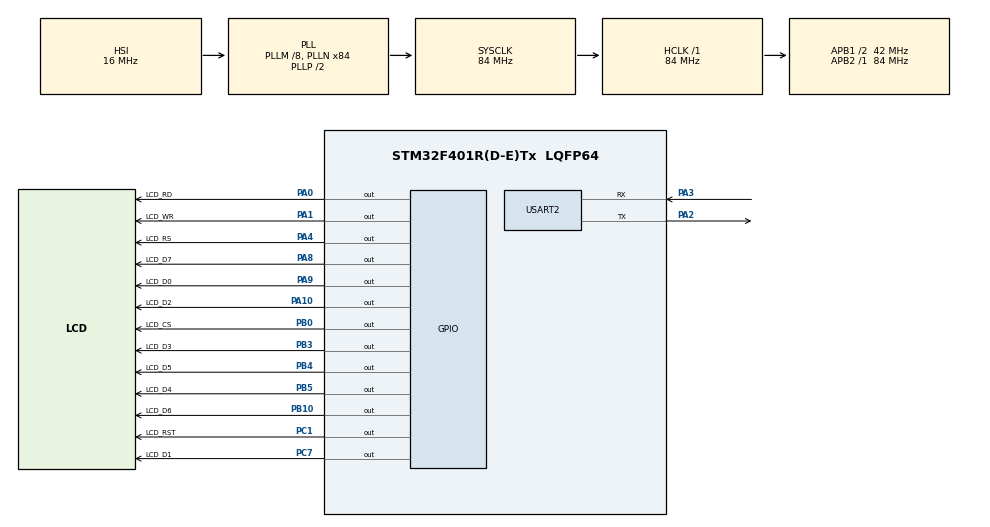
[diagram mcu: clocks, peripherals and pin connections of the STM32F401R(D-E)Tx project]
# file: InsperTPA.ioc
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Mcu.Family=STM32F4
Mcu.Name=STM32F401R(D-E)Tx
Mcu.Package=LQFP64
NVIC.PriorityGroup=NVIC_PRIORITYGROUP_4
NVIC.USART2_IRQn=true\:0\:0\:false\:false\:true\:true\:true\:true
PA0-WKUP.GPIO_Label=LCD_RD
PA0-WKUP.GPIO_PuPd=GPIO_PULLDOWN
PA0-WKUP.GPIO_Speed=GPIO_SPEED_FREQ_VERY_HIGH
PA0-WKUP.PinState=GPIO_PIN_SET
PA0-WKUP.Signal=GPIO_Output
PA1.GPIO_Label=LCD_WR
PA1.GPIO_PuPd=GPIO_PULLDOWN
PA1.GPIO_Speed=GPIO_SPEED_FREQ_VERY_HIGH
PA1.PinState=GPIO_PIN_SET
PA1.Signal=GPIO_Output
PA10.GPIO_Label=LCD_D2
PA10.GPIO_PuPd=GPIO_PULLDOWN
PA10.GPIO_Speed=GPIO_SPEED_FREQ_VERY_HIGH
PA10.Signal=GPIO_Output
PA2.Mode=Asynchronous
PA2.Signal=USART2_TX
PA3.Mode=Asynchronous
PA3.Signal=USART2_RX
PA4.GPIO_Label=LCD_RS
PA4.GPIO_PuPd=GPIO_PULLDOWN
PA4.GPIO_Speed=GPIO_SPEED_FREQ_VERY_HIGH
PA4.PinState=GPIO_PIN_SET
PA4.Signal=GPIO_Output
PA8.GPIO_Label=LCD_D7
PA8.GPIO_PuPd=GPIO_PULLDOWN
PA8.GPIO_Speed=GPIO_SPEED_FREQ_VERY_HIGH
PA8.Signal=GPIO_Output
PA9.GPIO_Label=LCD_D0
PA9.GPIO_PuPd=GPIO_PULLDOWN
PA9.GPIO_Speed=GPIO_SPEED_FREQ_VERY_HIGH
PA9.Signal=GPIO_Output
PB0.GPIO_Label=LCD_CS
PB0.GPIO_PuPd=GPIO_PULLDOWN
PB0.GPIO_Speed=GPIO_SPEED_FREQ_VERY_HIGH
PB0.PinState=GPIO_PIN_SET
PB0.Signal=GPIO_Output
PB10.GPIO_Label=LCD_D6
PB10.GPIO_PuPd=GPIO_PULLDOWN
PB10.GPIO_Speed=GPIO_SPEED_FREQ_VERY_HIGH
PB10.Signal=GPIO_Output
PB3.GPIO_Label=LCD_D3
PB3.GPIO_PuPd=GPIO_PULLDOWN
PB3.GPIO_Speed=GPIO_SPEED_FREQ_VERY_HIGH
PB3.Signal=GPIO_Output
PB4.GPIO_Label=LCD_D5
PB4.GPIO_PuPd=GPIO_PULLDOWN
PB4.GPIO_Speed=GPIO_SPEED_FREQ_VERY_HIGH
PB4.Signal=GPIO_Output
PB5.GPIO_Label=LCD_D4
PB5.GPIO_PuPd=GPIO_PULLDOWN
PB5.GPIO_Speed=GPIO_SPEED_FREQ_VERY_HIGH
PB5.Signal=GPIO_Output
PC1.GPIO_Label=LCD_RST
PC1.GPIO_ModeDefaultOutputPP=GPIO_MODE_OUTPUT_PP
PC1.GPIO_PuPd=GPIO_PULLUP
PC1.GPIO_Speed=GPIO_SPEED_FREQ_VERY_HIGH
PC1.PinState=GPIO_PIN_SET
PC1.Signal=GPIO_Output
PC7.GPIO_Label=LCD_D1
PC7.GPIO_PuPd=GPIO_PULLDOWN
PC7.GPIO_Speed=GPIO_SPEED_FREQ_VERY_HIGH
PC7.Signal=GPIO_Output
ProjectManager.HeapSize=0x200
ProjectManager.StackSize=0x400
ProjectManager.TargetToolchain=STM32CubeIDE
RCC.48MHZClocksFreq_Value=42000000
RCC.AHBFreq_Value=84000000
RCC.APB1CLKDivider=RCC_HCLK_DIV2
RCC.APB1Freq_Value=42000000
RCC.APB1TimFreq_Value=84000000
RCC.APB2Freq_Value=84000000
RCC.APB2TimFreq_Value=84000000
RCC.CortexFreq_Value=84000000
RCC.FLatency=FLASH_LATENCY_2
RCC.HCLKFreq_Value=84000000
RCC.HSE_VALUE=25000000
RCC.HSI_VALUE=16000000
RCC.LSE_VALUE=32768
RCC.PLLM=8
RCC.PLLN=84
RCC.SYSCLKFreq_VALUE=84000000
RCC.SYSCLKSource=RCC_SYSCLKSOURCE_PLLCLK
RCC.VCOOutputFreq_Value=168000000
STMicroelectronics.X-CUBE-TOUCHGFX.4.26.1.ApplicationCcGraphicsJjApplication=TouchGFXOoGenerator
STMicroelectronics.X-CUBE-TOUCHGFX.4.26.1.tgfx_block_size=19200
STMicroelectronics.X-CUBE-TOUCHGFX.4.26.1.tgfx_buffering_strategy=Partial
STMicroelectronics.X-CUBE-TOUCHGFX.4.26.1.tgfx_custom_height=320
STMicroelectronics.X-CUBE-TOUCHGFX.4.26.1.tgfx_custom_width=240
STMicroelectronics.X-CUBE-TOUCHGFX.4.26.1.tgfx_number_of_blocks=2
STMicroelectronics.X-CUBE-TOUCHGFX.4.26.1_IsPackSelfContextualization=true
USART2.VirtualMode=VM_ASYNC
VP_CRC_VS_CRC.Mode=CRC_Activate
VP_STMicroelectronics.X-CUBE-TOUCHGFX_VS_GraphicsJjApplication_4.26.1.Mode=GraphicsJjApplication
board=custom

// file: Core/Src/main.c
/* USER CODE BEGIN Header */
/**
  ******************************************************************************
  * @file           : main.c
  * @brief          : Main program body
  ******************************************************************************
  * @attention
  *
  * Copyright (c) 2026 STMicroelectronics.
  * All rights reserved.
  *
  * This software is licensed under terms that can be found in the LICENSE file
  * in the root directory of this software component.
  * If no LICENSE file comes with this software, it is provided AS-IS.
  *
  ******************************************************************************
  */
/* USER CODE END Header */
#include "main.h"
#include "app_touchgfx.h"

/* USER CODE BEGIN Includes */
//#include <gui_generated/screen2_screen/Screen2ViewBase.hpp>
//#include <gui_generated/screen1_screen/Screen1ViewBase.hpp>
/* USER CODE END Includes */

CRC_HandleTypeDef hcrc;

UART_HandleTypeDef huart2;

void SystemClock_Config(void);
static void MX_GPIO_Init(void);
static void MX_CRC_Init(void);
static void MX_USART2_UART_Init(void);
/* USER CODE BEGIN PFP */
void touchgfxSignalVSync(void);
/* USER CODE END PFP */

/* USER CODE BEGIN 0 */
volatile char changeScreen = 0;
uint8_t pu8DataBuf[2] = {0,0};
/* USER CODE END 0 */

int main(void)
{

  /* MCU Configuration--------------------------------------------------------*/

  /* Reset of all peripherals, Initializes the Flash interface and the Systick. */
  HAL_Init();

  /* Configure the system clock */
  SystemClock_Config();

  /* Initialize all configured peripherals */
  MX_GPIO_Init();
  MX_CRC_Init();
  MX_USART2_UART_Init();
  MX_TouchGFX_Init();
  /* USER CODE BEGIN 2 */
  HAL_UART_Receive_IT(&huart2, pu8DataBuf, 1);
  /* USER CODE END 2 */

  /* Infinite loop */
  while (1)
  {

	  MX_TouchGFX_Process();
	  /* USER CODE BEGIN 3 */
	  touchgfxSignalVSync();
	  if(pu8DataBuf[0] != 0)
	  {
		  if(pu8DataBuf[0] == 0x31)
		  {
			  changeScreen = 1;
		  }
		  else
		  {
			  changeScreen = 2;
		  }
		  pu8DataBuf[0] = 0;
	  }
  }
  /* USER CODE END 3 */
}

void SystemClock_Config(void)
{
  RCC_OscInitTypeDef RCC_OscInitStruct = {0};
  RCC_ClkInitTypeDef RCC_ClkInitStruct = {0};

  /** Configure the main internal regulator output voltage
  */
  __HAL_RCC_PWR_CLK_ENABLE();
  __HAL_PWR_VOLTAGESCALING_CONFIG(PWR_REGULATOR_VOLTAGE_SCALE2);

  /** Initializes the RCC Oscillators according to the specified parameters
  * in the RCC_OscInitTypeDef structure.
  */
  RCC_OscInitStruct.OscillatorType = RCC_OSCILLATORTYPE_HSI;
  RCC_OscInitStruct.HSIState = RCC_HSI_ON;
  RCC_OscInitStruct.HSICalibrationValue = RCC_HSICALIBRATION_DEFAULT;
  RCC_OscInitStruct.PLL.PLLState = RCC_PLL_ON;
  RCC_OscInitStruct.PLL.PLLSource = RCC_PLLSOURCE_HSI;
  RCC_OscInitStruct.PLL.PLLM = 8;
  RCC_OscInitStruct.PLL.PLLN = 84;
  RCC_OscInitStruct.PLL.PLLP = RCC_PLLP_DIV2;
  RCC_OscInitStruct.PLL.PLLQ = 4;
  if (HAL_RCC_OscConfig(&RCC_OscInitStruct) != HAL_OK)
  {
    Error_Handler();
  }

  /** Initializes the CPU, AHB and APB buses clocks
  */
  RCC_ClkInitStruct.ClockType = RCC_CLOCKTYPE_HCLK|RCC_CLOCKTYPE_SYSCLK
                              |RCC_CLOCKTYPE_PCLK1|RCC_CLOCKTYPE_PCLK2;
  RCC_ClkInitStruct.SYSCLKSource = RCC_SYSCLKSOURCE_PLLCLK;
  RCC_ClkInitStruct.AHBCLKDivider = RCC_SYSCLK_DIV1;
  RCC_ClkInitStruct.APB1CLKDivider = RCC_HCLK_DIV2;
  RCC_ClkInitStruct.APB2CLKDivider = RCC_HCLK_DIV1;

  if (HAL_RCC_ClockConfig(&RCC_ClkInitStruct, FLASH_LATENCY_2) != HAL_OK)
  {
    Error_Handler();
  }
}

static void MX_CRC_Init(void)
{

  hcrc.Instance = CRC;
  if (HAL_CRC_Init(&hcrc) != HAL_OK)
  {
    Error_Handler();
  }

}

static void MX_USART2_UART_Init(void)
{

  huart2.Instance = USART2;
  huart2.Init.BaudRate = 115200;
  huart2.Init.WordLength = UART_WORDLENGTH_8B;
  huart2.Init.StopBits = UART_STOPBITS_1;
  huart2.Init.Parity = UART_PARITY_NONE;
  huart2.Init.Mode = UART_MODE_TX_RX;
  huart2.Init.HwFlowCtl = UART_HWCONTROL_NONE;
  huart2.Init.OverSampling = UART_OVERSAMPLING_16;
  if (HAL_UART_Init(&huart2) != HAL_OK)
  {
    Error_Handler();
  }

}

static void MX_GPIO_Init(void)
{
  GPIO_InitTypeDef GPIO_InitStruct = {0};

  /* GPIO Ports Clock Enable */
  __HAL_RCC_GPIOC_CLK_ENABLE();
  __HAL_RCC_GPIOA_CLK_ENABLE();
  __HAL_RCC_GPIOB_CLK_ENABLE();

  /*Configure GPIO pin Output Level */
  HAL_GPIO_WritePin(LCD_RST_GPIO_Port, LCD_RST_Pin, GPIO_PIN_SET);

  /*Configure GPIO pin Output Level */
  HAL_GPIO_WritePin(GPIOA, LCD_RD_Pin|LCD_WR_Pin|LCD_RS_Pin, GPIO_PIN_SET);

  /*Configure GPIO pin Output Level */
  HAL_GPIO_WritePin(LCD_CS_GPIO_Port, LCD_CS_Pin, GPIO_PIN_SET);

  /*Configure GPIO pin Output Level */
  HAL_GPIO_WritePin(GPIOB, LCD_D6_Pin|LCD_D3_Pin|LCD_D5_Pin|LCD_D4_Pin, GPIO_PIN_RESET);

  /*Configure GPIO pin Output Level */
  HAL_GPIO_WritePin(LCD_D1_GPIO_Port, LCD_D1_Pin, GPIO_PIN_RESET);

  /*Configure GPIO pin Output Level */
  HAL_GPIO_WritePin(GPIOA, LCD_D7_Pin|LCD_D0_Pin|LCD_D2_Pin, GPIO_PIN_RESET);

  /*Configure GPIO pin : LCD_RST_Pin */
  GPIO_InitStruct.Pin = LCD_RST_Pin;
  GPIO_InitStruct.Mode = GPIO_MODE_OUTPUT_PP;
  GPIO_InitStruct.Pull = GPIO_PULLUP;
  GPIO_InitStruct.Speed = GPIO_SPEED_FREQ_VERY_HIGH;
  HAL_GPIO_Init(LCD_RST_GPIO_Port, &GPIO_InitStruct);

  /*Configure GPIO pins : LCD_RD_Pin LCD_WR_Pin LCD_RS_Pin LCD_D7_Pin
                           LCD_D0_Pin LCD_D2_Pin */
  GPIO_InitStruct.Pin = LCD_RD_Pin|LCD_WR_Pin|LCD_RS_Pin|LCD_D7_Pin
                          |LCD_D0_Pin|LCD_D2_Pin;
  GPIO_InitStruct.Mode = GPIO_MODE_OUTPUT_PP;
  GPIO_InitStruct.Pull = GPIO_PULLDOWN;
  GPIO_InitStruct.Speed = GPIO_SPEED_FREQ_VERY_HIGH;
  HAL_GPIO_Init(GPIOA, &GPIO_InitStruct);

  /*Configure GPIO pins : LCD_CS_Pin LCD_D6_Pin LCD_D3_Pin LCD_D5_Pin
                           LCD_D4_Pin */
  GPIO_InitStruct.Pin = LCD_CS_Pin|LCD_D6_Pin|LCD_D3_Pin|LCD_D5_Pin
                          |LCD_D4_Pin;
  GPIO_InitStruct.Mode = GPIO_MODE_OUTPUT_PP;
  GPIO_InitStruct.Pull = GPIO_PULLDOWN;
  GPIO_InitStruct.Speed = GPIO_SPEED_FREQ_VERY_HIGH;
  HAL_GPIO_Init(GPIOB, &GPIO_InitStruct);

  /*Configure GPIO pin : LCD_D1_Pin */
  GPIO_InitStruct.Pin = LCD_D1_Pin;
  GPIO_InitStruct.Mode = GPIO_MODE_OUTPUT_PP;
  GPIO_InitStruct.Pull = GPIO_PULLDOWN;
  GPIO_InitStruct.Speed = GPIO_SPEED_FREQ_VERY_HIGH;
  HAL_GPIO_Init(LCD_D1_GPIO_Port, &GPIO_InitStruct);

}

/* USER CODE BEGIN 4 */
void HAL_UART_RxCpltCallback(UART_HandleTypeDef *huart)
{
	 HAL_UART_Receive_IT(&huart2, pu8DataBuf, 1);
}
/* USER CODE END 4 */

void Error_Handler(void)
{
  __disable_irq();
  while (1)
  {
  }
}
